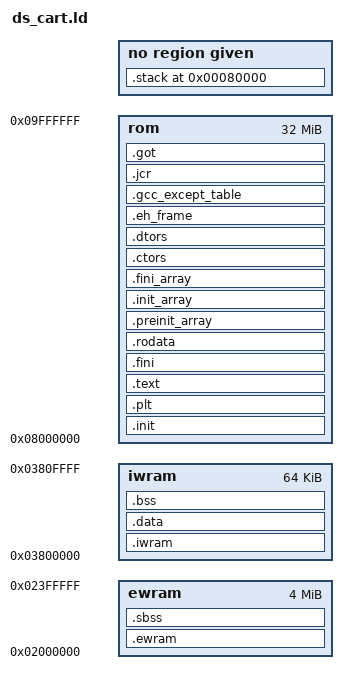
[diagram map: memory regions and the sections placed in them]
OUTPUT_FORMAT("elf32-littlearm", "elf32-bigarm", "elf32-littlearm")
OUTPUT_ARCH(arm)
ENTRY(_start)

MEMORY {

	rom	: ORIGIN = 0x08000000, LENGTH = 32M
	iwram	: ORIGIN = 0x03800000, LENGTH = 64K	
	ewram	: ORIGIN = 0x02000000, LENGTH = 4M
}

__ewram_start	=	ORIGIN(ewram);
__eheap_end	=	ORIGIN(ewram)+ LENGTH(ewram);
__iwram_start	=	ORIGIN(iwram);
__iwram_top	=	ORIGIN(iwram)+ LENGTH(iwram);
__sp_irq	=	__iwram_top - 0x60;
__sp_svc	=	__sp_irq - 0x100;
__sp_usr	=	__sp_svc - 0x100;

__irq_flags	=	__iwram_top - 8;
__irq_vector	=	__iwram_top - 4;

SECTIONS
{
	.init	:
	{
		__text_start = . ;
		KEEP (*(.init))
		. = ALIGN(4);  /* REQUIRED. LD is flaky without it. */
		} >rom = 0xff
	.plt : { *(.plt) } >rom = 0xff

	.text :   /* ALIGN (4): */
	{
		*(EXCLUDE_FILE (*.iwram*) .text)
		*(.text .stub .text.* .gnu.linkonce.t.*)
		KEEP (*(.text.*personality*))
		/* .gnu.warning sections are handled specially by elf32.em.  */
		*(.gnu.warning)
		*(.glue_7t) *(.glue_7) *(.vfp11_veneer)
		. = ALIGN(4);  /* REQUIRED. LD is flaky without it. */
	} >rom = 0xff

	.fini           :
	{
		KEEP (*(.fini))
	} >rom =0xff

	__text_end = . ;

	.rodata :
	{
		*(.rodata)
		*all.rodata*(*)
		*(.roda)
		*(.rodata.*)
		*(.gnu.linkonce.r*)
		SORT(CONSTRUCTORS)
		. = ALIGN(4);   /* REQUIRED. LD is flaky without it. */
	} >rom = 0xff

  /* Ensure the __preinit_array_start label is properly aligned.  We
     could instead move the label definition inside the section, but
     the linker would then create the section even if it turns out to
     be empty, which isn't pretty.  */
  . = ALIGN(32 / 8);
  PROVIDE (__preinit_array_start = .);
  .preinit_array     : { KEEP (*(.preinit_array)) } >rom = 0xff
  PROVIDE (__preinit_array_end = .);
  PROVIDE (__init_array_start = .);
  .init_array     : { KEEP (*(.init_array)) } >rom = 0xff
  PROVIDE (__init_array_end = .);
  PROVIDE (__fini_array_start = .);
  .fini_array     : { KEEP (*(.fini_array)) } >rom = 0xff
  PROVIDE (__fini_array_end = .);

	.ctors :
	{
	/* gcc uses crtbegin.o to find the start of the constructors, so
		we make sure it is first.  Because this is a wildcard, it
		doesn't matter if the user does not actually link against
		crtbegin.o; the linker won't look for a file to match a
		wildcard.  The wildcard also means that it doesn't matter which
		directory crtbegin.o is in.  */
		KEEP (*crtbegin.o(.ctors))
		KEEP (*(EXCLUDE_FILE (*crtend.o) .ctors))
		KEEP (*(SORT(.ctors.*)))
		KEEP (*(.ctors))
		. = ALIGN(4);   /* REQUIRED. LD is flaky without it. */
	} >rom = 0xff

	.dtors :
	{
		KEEP (*crtbegin.o(.dtors))
		KEEP (*(EXCLUDE_FILE (*crtend.o) .dtors))
		KEEP (*(SORT(.dtors.*)))
		KEEP (*(.dtors))
		. = ALIGN(4);   /* REQUIRED. LD is flaky without it. */
	} >rom = 0xff

	.eh_frame :
	{
		KEEP (*(.eh_frame))
		. = ALIGN(4);   /* REQUIRED. LD is flaky without it. */
	} >rom = 0xff

	.gcc_except_table :
	{
		*(.gcc_except_table)
		. = ALIGN(4);   /* REQUIRED. LD is flaky without it. */
	} >rom = 0xff
	.jcr            : { KEEP (*(.jcr)) } >rom = 0
	.got            : { *(.got.plt) *(.got) } >rom = 0

	__ewram_lma = . ;

	.ewram __ewram_start : AT (__ewram_lma) 
	{
		__ewram_start = ABSOLUTE(.) ;
		*(.ewram)
		*ewram.*(.text)
		. = ALIGN(4);   /* REQUIRED. LD is flaky without it. */
	} >ewram = 0xff

	.sbss ALIGN(4):
 	{
		__sbss_start = ABSOLUTE(.);
 		*(.sbss)
 		. = ALIGN(4);
 	} >ewram
	__sbss_end = . ;

	_end = . ;
	__end__ = . ;
	PROVIDE (end = _end);

	__iwram_lma = __ewram_lma + SIZEOF(.ewram) + SIZEOF(.sbss);
	
	.iwram __iwram_start : AT (__iwram_lma)
	{
		__iwram_start = ABSOLUTE(.) ;
		*(.iwram)
		*iwram.*(.text)
		. = ALIGN(4);   /* REQUIRED. LD is flaky without it. */
	} >iwram = 0xff

	__iwram_end = . ;
	__data_lma = __iwram_lma + SIZEOF(.iwram) ;


	.data ALIGN(4) : AT (__data_lma)
	{
		__data_start = ABSOLUTE(.);
		*(.data)
		*(.data.*)
		*(.gnu.linkonce.d*)
		CONSTRUCTORS
		. = ALIGN(4);
	} >iwram = 0xff

	__data_end = . ;
	__appended_data = __data_lma + SIZEOF(.data) ;


	.bss ALIGN(4) :
	{
		__bss_start = ABSOLUTE(.);
		__bss_start__ = ABSOLUTE(.);
		*(.dynbss)
		*(.gnu.linkonce.b*)
		*(.bss*)
		*(COMMON)
		. = ALIGN(4);    /* REQUIRED. LD is flaky without it. */
		__bss_end__ = ABSOLUTE(.);
		__end__ = ABSOLUTE(.);
	} >iwram

	/* Stabs debugging sections.  */
	.stab 0 : { *(.stab) }
	.stabstr 0 : { *(.stabstr) }
	.stab.excl 0 : { *(.stab.excl) }
	.stab.exclstr 0 : { *(.stab.exclstr) }
	.stab.index 0 : { *(.stab.index) }
	.stab.indexstr 0 : { *(.stab.indexstr) }
	.comment 0 : { *(.comment) }
	/*	DWARF debug sections.
		Symbols in the DWARF debugging sections are relative to the beginning
		of the section so we begin them at 0.  */
	/* DWARF 1 */
	.debug          0 : { *(.debug) }
	.line           0 : { *(.line) }
	/* GNU DWARF 1 extensions */
	.debug_srcinfo  0 : { *(.debug_srcinfo) }
	.debug_sfnames  0 : { *(.debug_sfnames) }
	/* DWARF 1.1 and DWARF 2 */
	.debug_aranges  0 : { *(.debug_aranges) }
	.debug_pubnames 0 : { *(.debug_pubnames) }
	/* DWARF 2 */
	.debug_info     0 : { *(.debug_info) }
	.debug_abbrev   0 : { *(.debug_abbrev) }
	.debug_line     0 : { *(.debug_line) }
	.debug_frame    0 : { *(.debug_frame) }
	.debug_str      0 : { *(.debug_str) }
	.debug_loc      0 : { *(.debug_loc) }
	.debug_macinfo  0 : { *(.debug_macinfo) }
	/* SGI/MIPS DWARF 2 extensions */
	.debug_weaknames 0 : { *(.debug_weaknames) }
	.debug_funcnames 0 : { *(.debug_funcnames) }
	.debug_typenames 0 : { *(.debug_typenames) }
	.debug_varnames  0 : { *(.debug_varnames) }
	.stack 0x80000 : { _stack = .; *(.stack) }
	/* These must appear regardless of  .  */
}
